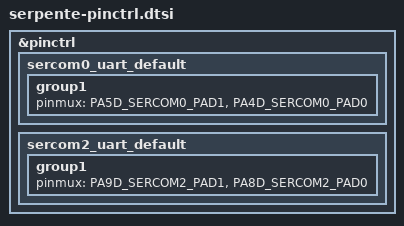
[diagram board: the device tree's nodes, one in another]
/*
 * Copyright (c) 2022, Gerson Fernando Budke <nandojve@gmail.com>
 * SPDX-License-Identifier: Apache-2.0
 */

#include <dt-bindings/pinctrl/samd21-da1eXabcd-pinctrl.h>

&pinctrl {
	sercom0_uart_default: sercom0_uart_default {
		group1 {
			pinmux = <PA5D_SERCOM0_PAD1>,
				 <PA4D_SERCOM0_PAD0>;
		};
	};
	sercom2_uart_default: sercom2_uart_default {
		group1 {
			pinmux = <PA9D_SERCOM2_PAD1>,
				 <PA8D_SERCOM2_PAD0>;
		};
	};
};
